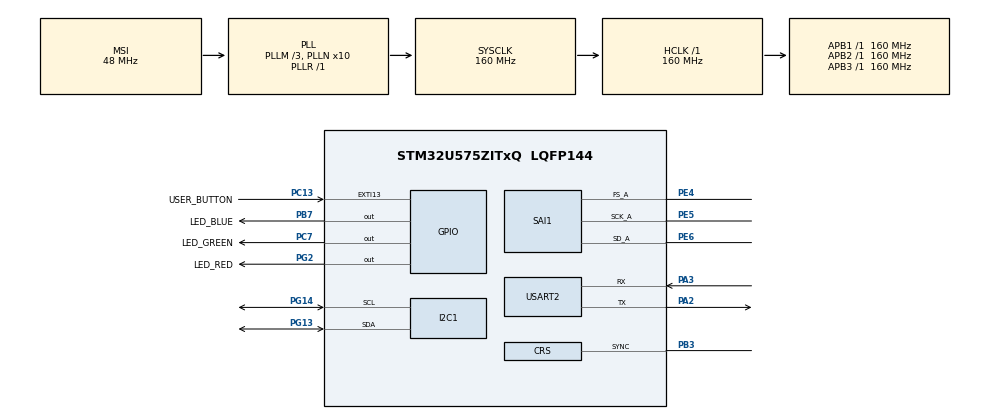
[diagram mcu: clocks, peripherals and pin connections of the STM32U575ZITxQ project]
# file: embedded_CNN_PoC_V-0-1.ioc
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CORTEX_M33_NS.userName=CORTEX_M33
I2C1.Timing=0x00000E14
Mcu.Family=STM32U5
Mcu.Name=STM32U575ZITxQ
Mcu.Package=LQFP144
NVIC.PriorityGroup=NVIC_PRIORITYGROUP_3
NVIC.SAI1_IRQn=true\:0\:0\:false\:false\:true\:false\:true\:true
NVIC.TIM17_IRQn=true\:7\:0\:false\:false\:true\:false\:false\:true
NVIC.TimeBase=TIM17_IRQn
NVIC.TimeBaseIP=TIM17
PA2.Mode=Asynchronous
PA2.Signal=USART2_TX
PA3.Mode=Asynchronous
PA3.Signal=USART2_RX
PB3\ (JTDO/TRACESWO).Mode=CRS SYNC Source GPIO
PB3\ (JTDO/TRACESWO).Signal=CRS_SYNC
PB7.GPIO_Label=LED_BLUE
PB7.Signal=GPIO_Output
PC13.GPIO_Label=USER_BUTTON
PC13.Signal=GPXTI13
PC7.GPIO_Label=LED_GREEN
PC7.Signal=GPIO_Output
PE4.Mode=SAI_A_Master
PE4.Signal=SAI1_FS_A
PE5.Mode=SAI_A_Master
PE5.Signal=SAI1_SCK_A
PE6.Mode=SAI_A_Master
PE6.Signal=SAI1_SD_A
PG13.Mode=I2C
PG13.Signal=I2C1_SDA
PG14.Mode=I2C
PG14.Signal=I2C1_SCL
PG2.GPIO_Label=LED_RED
PG2.Signal=GPIO_Output
PH0-OSC_IN\ (PH0).Mode=HSE-External-Oscillator
PH0-OSC_IN\ (PH0).Signal=RCC_OSC_IN
PH1-OSC_OUT\ (PH1).Mode=HSE-External-Oscillator
PH1-OSC_OUT\ (PH1).Signal=RCC_OSC_OUT
ProjectManager.HeapSize=0x800
ProjectManager.StackSize=0x800
ProjectManager.TargetToolchain=STM32CubeIDE
RCC.ADCCLockSelection=RCC_ADCDACCLKSOURCE_PLL2
RCC.ADCFreq_Value=160000000
RCC.AHBFreq_Value=160000000
RCC.APB1Freq_Value=160000000
RCC.APB1TimFreq_Value=160000000
RCC.APB2Freq_Value=160000000
RCC.APB2TimFreq_Value=160000000
RCC.APB3Freq_Value=160000000
RCC.CortexFreq_Value=160000000
RCC.DACCLockSelectionVirtual=RCC_DAC1CLKSOURCE_LSI
RCC.DACCLockSelectionVirtualString=RCC_DAC1CLKSOURCE_LSI
RCC.EPOD_VALUE=48000000
RCC.HCLKFreq_Value=160000000
RCC.HSE_VALUE=16000000
RCC.HSI48_VALUE=48000000
RCC.HSI_VALUE=16000000
RCC.LSE_VALUE=32768
RCC.LSIDIV_VALUE=32000
RCC.MSIClockRange=RCC_MSIRANGE_0
RCC.MSI_VALUE=48000000
RCC.PLL1R=1
RCC.PLL2M=3
RCC.PLL2N=20
RCC.PLL2P=4
RCC.PLLM=3
RCC.PLLN=10
RCC.PWR_Regulator_Voltage_Scale=PWR_REGULATOR_VOLTAGE_SCALE1
RCC.SYSCLKFreq_VALUE=160000000
RCC.SYSCLKSource=RCC_SYSCLKSOURCE_PLLCLK
RCC.USBFreq_Value=48000000
RCC.VCOOutputFreq_Value=160000000
SAI1.AudioFrequency-SAI_A_Master=SAI_AUDIO_FREQUENCY_48K
SAI1.AudioMode-SAI_A_Master=SAI_MODEMASTER_RX
SAI1.BasicDataSize-SAI_A_Master=SAI_PROTOCOL_DATASIZE_24BIT
SAI1.ErrorAudioFreq-SAI_A_Master=4.97 %
SAI1.InitProtocol-SAI_A_Master=Enable
SAI1.Instance-SAI_A_Master=SAI$Index_Block_A
SAI1.MckOutput-SAI_A_Master=SAI_MCK_OUTPUT_DISABLE
SAI1.MonoStereoMode-SAI_A_Master=SAI_MONOMODE
SAI1.RealAudioFreq-SAI_A_Master=50.39 KHz
SAI1.VirtualMode-SAI_A_Master=VM_MASTER
SAI1.VirtualProtocol-SAI_A_BASIC=VM_BASIC_PROTOCOL
STMicroelectronics.X-CUBE-AI.7.1.0.ActivationBufferSizeList=46300
STMicroelectronics.X-CUBE-AI.7.1.0.ActivationBuffers=pool0
STMicroelectronics.X-CUBE-AI.7.1.0.ActivationNames=pool0
STMicroelectronics.X-CUBE-AI.7.1.0.ActivationSizes=AI_N4CED_V02_DATA_ACTIVATION_1_SIZE
STMicroelectronics.X-CUBE-AI.7.1.0.HeapSize=0x800
STMicroelectronics.X-CUBE-AI.7.1.0.InternalRamActivationBufferMaxSize=AI_N4CED_V02_DATA_ACTIVATIONS_SIZE
STMicroelectronics.X-CUBE-AI.7.1.0.MaximumNumberOfInputLayer=1
STMicroelectronics.X-CUBE-AI.7.1.0.MaximumNumberOfOutputLayer=1
STMicroelectronics.X-CUBE-AI.7.1.0.MaximumSizeOfInputLayer=AI_N4CED_V02_IN_1_SIZE_BYTES
STMicroelectronics.X-CUBE-AI.7.1.0.MaximumSizeOfOutputLayer=AI_N4CED_V02_OUT_1_SIZE_BYTES
STMicroelectronics.X-CUBE-AI.7.1.0.ModelActualCompression-a3839d4dfd1a3be76489f947041929f79b5a45c50f3c16e5534fa310360bc950=0.0
STMicroelectronics.X-CUBE-AI.7.1.0.ModelCompression-a3839d4dfd1a3be76489f947041929f79b5a45c50f3c16e5534fa310360bc950=1
STMicroelectronics.X-CUBE-AI.7.1.0.ModelFlashOccupation-a3839d4dfd1a3be76489f947041929f79b5a45c50f3c16e5534fa310360bc950=742236
STMicroelectronics.X-CUBE-AI.7.1.0.ModelHashList=a3839d4dfd1a3be76489f947041929f79b5a45c50f3c16e5534fa310360bc950
STMicroelectronics.X-CUBE-AI.7.1.0.ModelKind-a3839d4dfd1a3be76489f947041929f79b5a45c50f3c16e5534fa310360bc950=TFLITE
STMicroelectronics.X-CUBE-AI.7.1.0.ModelMacc-a3839d4dfd1a3be76489f947041929f79b5a45c50f3c16e5534fa310360bc950=5028040
STMicroelectronics.X-CUBE-AI.7.1.0.ModelName-a3839d4dfd1a3be76489f947041929f79b5a45c50f3c16e5534fa310360bc950=n4ced_v02
STMicroelectronics.X-CUBE-AI.7.1.0.ModelNameList=n4ced_v02
STMicroelectronics.X-CUBE-AI.7.1.0.ModelRamOccupation-a3839d4dfd1a3be76489f947041929f79b5a45c50f3c16e5534fa310360bc950=46300
STMicroelectronics.X-CUBE-AI.7.1.0.ModelStructureFile-a3839d4dfd1a3be76489f947041929f79b5a45c50f3c16e5534fa310360bc950=C\:\\Users\\j.tschavoll\\OneDrive - FH Vorarlberg\\Partnerunternehmen FHV\\FH\\BA\\Code\\Jupyter\\N4CED_V-0-2\\N4CED_V-0-2_lite.tflite
STMicroelectronics.X-CUBE-AI.7.1.0.ModelType-a3839d4dfd1a3be76489f947041929f79b5a45c50f3c16e5534fa310360bc950=STM32Cube.AI runtime
STMicroelectronics.X-CUBE-AI.7.1.0.ReadyForCodeGeneration=true
STMicroelectronics.X-CUBE-AI.7.1.0.StackSize=0x800
STMicroelectronics.X-CUBE-AI.7.1.0.WorkingBufferStartAddrList=0xFFFFFFFF
STMicroelectronics.X-CUBE-AI.7.1.0.XAaCUBEAaAICcArtificialOoIntelligenceJjCore=true
USART2.VirtualMode-Asynchronous=VM_ASYNC
VP_CRC_VS_CRC.Mode=CRC_Activate
VP_GPDMA1_VS_GPDMACH15.Mode=LINKEDLIST_GPDMACH15
VP_ICACHE_VS_ICACHE.Mode=DirectMappedCache
VP_PWR_VS_DBSignals.Mode=DisableDeadBatterySignals
VP_PWR_VS_SECSignals.Mode=Security/Privilege
VP_SAI1_VP_$IpInstance_SAIA_SAI_BASIC.Mode=SAI_A_BASIC
VP_STMicroelectronics.X-CUBE-AI_VS_ArtificialOoIntelligenceJjXAaCUBEAaAI_7.1.0.Mode=ArtificialOoIntelligenceJjXAaCUBEAaAI
VP_SYS_VS_tim17.Mode=TIM17
VP_THREADX_VS_RTOSJjThreadXJjCoreJjDefault.Mode=Core_Default
VP_THREADX_VS_RTOSJjThreadXJjLow_Power_Support.Mode=Low_Power_Support
board=NUCLEO-U575ZI-Q

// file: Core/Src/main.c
/* USER CODE BEGIN Header */
/**
  ******************************************************************************
  * @file           : main.c
  * @brief          : Main program body
  ******************************************************************************
  * @attention
  *
  * <h2><center>&copy; Copyright (c) 2022 STMicroelectronics.
  * All rights reserved.</center></h2>
  *
  * This software component is licensed by ST under BSD 3-Clause license,
  * the "License"; You may not use this file except in compliance with the
  * License. You may obtain a copy of the License at:
  *                        opensource.org/licenses/BSD-3-Clause
  *
  ******************************************************************************
  */
/* USER CODE END Header */
#include "main.h"
#include "app_threadx.h"

CRC_HandleTypeDef hcrc;

DMA_HandleTypeDef handle_GPDMA1_Channel15;

I2C_HandleTypeDef hi2c1;

SAI_HandleTypeDef hsai_BlockA1;

UART_HandleTypeDef huart2;

/* USER CODE BEGIN PV */

#include "run.h"

/* USER CODE END PV */

void SystemClock_Config(void);
static void MX_GPIO_Init(void);
static void MX_GPDMA1_Init(void);
static void MX_I2C1_Init(void);
static void MX_ICACHE_Init(void);
static void MX_SAI1_Init(void);
static void MX_USART2_UART_Init(void);
static void MX_CRC_Init(void);

int main(void)
{

  /* MCU Configuration--------------------------------------------------------*/

  /* Reset of all peripherals, Initializes the Flash interface and the Systick. */
  HAL_Init();
  HAL_PWREx_EnableVddIO2();

  /* Configure the system clock */
  SystemClock_Config();

  /* Initialize all configured peripherals */
  MX_GPIO_Init();
  MX_GPDMA1_Init();
  MX_I2C1_Init();
  MX_ICACHE_Init();
  MX_SAI1_Init();
  MX_USART2_UART_Init();
  MX_CRC_Init();

  MX_ThreadX_Init();
  /* Infinite loop */
  /* USER CODE BEGIN WHILE */

  run();

  while (1)
  {
    /* USER CODE END WHILE */

  }
}

void SystemClock_Config(void)
{
  RCC_OscInitTypeDef RCC_OscInitStruct = {0};
  RCC_ClkInitTypeDef RCC_ClkInitStruct = {0};
  RCC_CRSInitTypeDef RCC_CRSInitStruct = {0};

  /** Configure the main internal regulator output voltage
  */
  if (HAL_PWREx_ControlVoltageScaling(PWR_REGULATOR_VOLTAGE_SCALE1) != HAL_OK)
  {
    Error_Handler();
  }
  /** Initializes the CPU, AHB and APB busses clocks
  */
  RCC_OscInitStruct.OscillatorType = RCC_OSCILLATORTYPE_HSI48|RCC_OSCILLATORTYPE_MSI;
  RCC_OscInitStruct.HSI48State = RCC_HSI48_ON;
  RCC_OscInitStruct.MSIState = RCC_MSI_ON;
  RCC_OscInitStruct.MSICalibrationValue = RCC_MSICALIBRATION_DEFAULT;
  RCC_OscInitStruct.MSIClockRange = RCC_MSIRANGE_0;
  RCC_OscInitStruct.PLL.PLLState = RCC_PLL_ON;
  RCC_OscInitStruct.PLL.PLLSource = RCC_PLLSOURCE_MSI;
  RCC_OscInitStruct.PLL.PLLMBOOST = RCC_PLLMBOOST_DIV4;
  RCC_OscInitStruct.PLL.PLLM = 3;
  RCC_OscInitStruct.PLL.PLLN = 10;
  RCC_OscInitStruct.PLL.PLLP = 2;
  RCC_OscInitStruct.PLL.PLLQ = 2;
  RCC_OscInitStruct.PLL.PLLR = 1;
  RCC_OscInitStruct.PLL.PLLRGE = RCC_PLLVCIRANGE_1;
  RCC_OscInitStruct.PLL.PLLFRACN = 0;
  if (HAL_RCC_OscConfig(&RCC_OscInitStruct) != HAL_OK)
  {
    Error_Handler();
  }
  /** Initializes the CPU, AHB and APB busses clocks
  */
  RCC_ClkInitStruct.ClockType = RCC_CLOCKTYPE_HCLK|RCC_CLOCKTYPE_SYSCLK
                              |RCC_CLOCKTYPE_PCLK1|RCC_CLOCKTYPE_PCLK2
                              |RCC_CLOCKTYPE_PCLK3;
  RCC_ClkInitStruct.SYSCLKSource = RCC_SYSCLKSOURCE_PLLCLK;
  RCC_ClkInitStruct.AHBCLKDivider = RCC_SYSCLK_DIV1;
  RCC_ClkInitStruct.APB1CLKDivider = RCC_HCLK_DIV1;
  RCC_ClkInitStruct.APB2CLKDivider = RCC_HCLK_DIV1;
  RCC_ClkInitStruct.APB3CLKDivider = RCC_HCLK_DIV1;

  if (HAL_RCC_ClockConfig(&RCC_ClkInitStruct, FLASH_LATENCY_4) != HAL_OK)
  {
    Error_Handler();
  }
  /** Enable the SYSCFG APB clock
  */
  __HAL_RCC_CRS_CLK_ENABLE();
  /** Configures CRS
  */
  RCC_CRSInitStruct.Prescaler = RCC_CRS_SYNC_DIV1;
  RCC_CRSInitStruct.Source = RCC_CRS_SYNC_SOURCE_GPIO;
  RCC_CRSInitStruct.Polarity = RCC_CRS_SYNC_POLARITY_RISING;
  RCC_CRSInitStruct.ReloadValue = __HAL_RCC_CRS_RELOADVALUE_CALCULATE(48000000,1);
  RCC_CRSInitStruct.ErrorLimitValue = 34;
  RCC_CRSInitStruct.HSI48CalibrationValue = 32;

  HAL_RCCEx_CRSConfig(&RCC_CRSInitStruct);
  __HAL_RCC_PWR_CLK_DISABLE();
}

static void MX_CRC_Init(void)
{

  hcrc.Instance = CRC;
  hcrc.Init.DefaultPolynomialUse = DEFAULT_POLYNOMIAL_ENABLE;
  hcrc.Init.DefaultInitValueUse = DEFAULT_INIT_VALUE_ENABLE;
  hcrc.Init.InputDataInversionMode = CRC_INPUTDATA_INVERSION_NONE;
  hcrc.Init.OutputDataInversionMode = CRC_OUTPUTDATA_INVERSION_DISABLE;
  hcrc.InputDataFormat = CRC_INPUTDATA_FORMAT_BYTES;
  if (HAL_CRC_Init(&hcrc) != HAL_OK)
  {
    Error_Handler();
  }

}

static void MX_GPDMA1_Init(void)
{

  /* Peripheral clock enable */
  __HAL_RCC_GPDMA1_CLK_ENABLE();

  handle_GPDMA1_Channel15.Instance = GPDMA1_Channel15;
  handle_GPDMA1_Channel15.InitLinkedList.Priority = DMA_LOW_PRIORITY_LOW_WEIGHT;
  handle_GPDMA1_Channel15.InitLinkedList.LinkStepMode = DMA_LSM_FULL_EXECUTION;
  handle_GPDMA1_Channel15.InitLinkedList.LinkAllocatedPort = DMA_LINK_ALLOCATED_PORT0;
  handle_GPDMA1_Channel15.InitLinkedList.TransferEventMode = DMA_TCEM_LAST_LL_ITEM_TRANSFER;
  handle_GPDMA1_Channel15.InitLinkedList.LinkedListMode = DMA_LINKEDLIST_NORMAL;
  if (HAL_DMAEx_List_Init(&handle_GPDMA1_Channel15) != HAL_OK)
  {
    Error_Handler();
  }
  if (HAL_DMA_ConfigChannelAttributes(&handle_GPDMA1_Channel15, DMA_CHANNEL_NPRIV) != HAL_OK)
  {
    Error_Handler();
  }

}

static void MX_I2C1_Init(void)
{

  hi2c1.Instance = I2C1;
  hi2c1.Init.Timing = 0x00000E14;
  hi2c1.Init.OwnAddress1 = 0;
  hi2c1.Init.AddressingMode = I2C_ADDRESSINGMODE_7BIT;
  hi2c1.Init.DualAddressMode = I2C_DUALADDRESS_DISABLE;
  hi2c1.Init.OwnAddress2 = 0;
  hi2c1.Init.OwnAddress2Masks = I2C_OA2_NOMASK;
  hi2c1.Init.GeneralCallMode = I2C_GENERALCALL_DISABLE;
  hi2c1.Init.NoStretchMode = I2C_NOSTRETCH_DISABLE;
  if (HAL_I2C_Init(&hi2c1) != HAL_OK)
  {
    Error_Handler();
  }
  /** Configure Analogue filter
  */
  if (HAL_I2CEx_ConfigAnalogFilter(&hi2c1, I2C_ANALOGFILTER_ENABLE) != HAL_OK)
  {
    Error_Handler();
  }
  /** Configure Digital filter
  */
  if (HAL_I2CEx_ConfigDigitalFilter(&hi2c1, 0) != HAL_OK)
  {
    Error_Handler();
  }

}

static void MX_ICACHE_Init(void)
{

  /** Enable instruction cache in 1-way (direct mapped cache)
  */
  if (HAL_ICACHE_ConfigAssociativityMode(ICACHE_1WAY) != HAL_OK)
  {
    Error_Handler();
  }
  if (HAL_ICACHE_Enable() != HAL_OK)
  {
    Error_Handler();
  }

}

static void MX_SAI1_Init(void)
{

  hsai_BlockA1.Instance = SAI1_Block_A;
  hsai_BlockA1.Init.AudioMode = SAI_MODEMASTER_RX;
  hsai_BlockA1.Init.Synchro = SAI_ASYNCHRONOUS;
  hsai_BlockA1.Init.OutputDrive = SAI_OUTPUTDRIVE_DISABLE;
  hsai_BlockA1.Init.NoDivider = SAI_MASTERDIVIDER_ENABLE;
  hsai_BlockA1.Init.FIFOThreshold = SAI_FIFOTHRESHOLD_EMPTY;
  hsai_BlockA1.Init.AudioFrequency = SAI_AUDIO_FREQUENCY_48K;
  hsai_BlockA1.Init.SynchroExt = SAI_SYNCEXT_DISABLE;
  hsai_BlockA1.Init.MonoStereoMode = SAI_MONOMODE;
  hsai_BlockA1.Init.CompandingMode = SAI_NOCOMPANDING;
  if (HAL_SAI_InitProtocol(&hsai_BlockA1, SAI_I2S_STANDARD, SAI_PROTOCOL_DATASIZE_24BIT, 2) != HAL_OK)
  {
    Error_Handler();
  }

}

static void MX_USART2_UART_Init(void)
{

  huart2.Instance = USART2;
  huart2.Init.BaudRate = 115200;
  huart2.Init.WordLength = UART_WORDLENGTH_8B;
  huart2.Init.StopBits = UART_STOPBITS_1;
  huart2.Init.Parity = UART_PARITY_NONE;
  huart2.Init.Mode = UART_MODE_TX_RX;
  huart2.Init.HwFlowCtl = UART_HWCONTROL_NONE;
  huart2.Init.OverSampling = UART_OVERSAMPLING_16;
  huart2.Init.OneBitSampling = UART_ONE_BIT_SAMPLE_DISABLE;
  huart2.Init.ClockPrescaler = UART_PRESCALER_DIV1;
  huart2.AdvancedInit.AdvFeatureInit = UART_ADVFEATURE_NO_INIT;
  if (HAL_UART_Init(&huart2) != HAL_OK)
  {
    Error_Handler();
  }
  if (HAL_UARTEx_SetTxFifoThreshold(&huart2, UART_TXFIFO_THRESHOLD_1_8) != HAL_OK)
  {
    Error_Handler();
  }
  if (HAL_UARTEx_SetRxFifoThreshold(&huart2, UART_RXFIFO_THRESHOLD_1_8) != HAL_OK)
  {
    Error_Handler();
  }
  if (HAL_UARTEx_DisableFifoMode(&huart2) != HAL_OK)
  {
    Error_Handler();
  }

}

static void MX_GPIO_Init(void)
{
  GPIO_InitTypeDef GPIO_InitStruct = {0};

  /* GPIO Ports Clock Enable */
  __HAL_RCC_GPIOE_CLK_ENABLE();
  __HAL_RCC_GPIOC_CLK_ENABLE();
  __HAL_RCC_GPIOH_CLK_ENABLE();
  __HAL_RCC_GPIOA_CLK_ENABLE();
  __HAL_RCC_GPIOG_CLK_ENABLE();
  __HAL_RCC_GPIOB_CLK_ENABLE();

  /*Configure GPIO pin Output Level */
  HAL_GPIO_WritePin(LED_RED_GPIO_Port, LED_RED_Pin, GPIO_PIN_RESET);

  /*Configure GPIO pin Output Level */
  HAL_GPIO_WritePin(LED_GREEN_GPIO_Port, LED_GREEN_Pin, GPIO_PIN_RESET);

  /*Configure GPIO pin Output Level */
  HAL_GPIO_WritePin(LED_BLUE_GPIO_Port, LED_BLUE_Pin, GPIO_PIN_RESET);

  /*Configure GPIO pin : USER_BUTTON_Pin */
  GPIO_InitStruct.Pin = USER_BUTTON_Pin;
  GPIO_InitStruct.Mode = GPIO_MODE_IT_RISING;
  GPIO_InitStruct.Pull = GPIO_NOPULL;
  HAL_GPIO_Init(USER_BUTTON_GPIO_Port, &GPIO_InitStruct);

  /*Configure GPIO pin : LED_RED_Pin */
  GPIO_InitStruct.Pin = LED_RED_Pin;
  GPIO_InitStruct.Mode = GPIO_MODE_OUTPUT_PP;
  GPIO_InitStruct.Pull = GPIO_NOPULL;
  GPIO_InitStruct.Speed = GPIO_SPEED_FREQ_LOW;
  HAL_GPIO_Init(LED_RED_GPIO_Port, &GPIO_InitStruct);

  /*Configure GPIO pin : LED_GREEN_Pin */
  GPIO_InitStruct.Pin = LED_GREEN_Pin;
  GPIO_InitStruct.Mode = GPIO_MODE_OUTPUT_PP;
  GPIO_InitStruct.Pull = GPIO_NOPULL;
  GPIO_InitStruct.Speed = GPIO_SPEED_FREQ_LOW;
  HAL_GPIO_Init(LED_GREEN_GPIO_Port, &GPIO_InitStruct);

  /*Configure GPIO pin : PB3 */
  GPIO_InitStruct.Pin = GPIO_PIN_3;
  GPIO_InitStruct.Mode = GPIO_MODE_AF_PP;
  GPIO_InitStruct.Pull = GPIO_NOPULL;
  GPIO_InitStruct.Speed = GPIO_SPEED_FREQ_LOW;
  GPIO_InitStruct.Alternate = GPIO_AF10_CRS;
  HAL_GPIO_Init(GPIOB, &GPIO_InitStruct);

  /*Configure GPIO pin : LED_BLUE_Pin */
  GPIO_InitStruct.Pin = LED_BLUE_Pin;
  GPIO_InitStruct.Mode = GPIO_MODE_OUTPUT_PP;
  GPIO_InitStruct.Pull = GPIO_NOPULL;
  GPIO_InitStruct.Speed = GPIO_SPEED_FREQ_LOW;
  HAL_GPIO_Init(LED_BLUE_GPIO_Port, &GPIO_InitStruct);

}

void HAL_TIM_PeriodElapsedCallback(TIM_HandleTypeDef *htim)
{
  if (htim->Instance == TIM17) {
    HAL_IncTick();
  }
}

void Error_Handler(void)
{
  __disable_irq();
  while (1)
  {
  }
}

/************************ (C) COPYRIGHT STMicroelectronics *****END OF FILE****/
